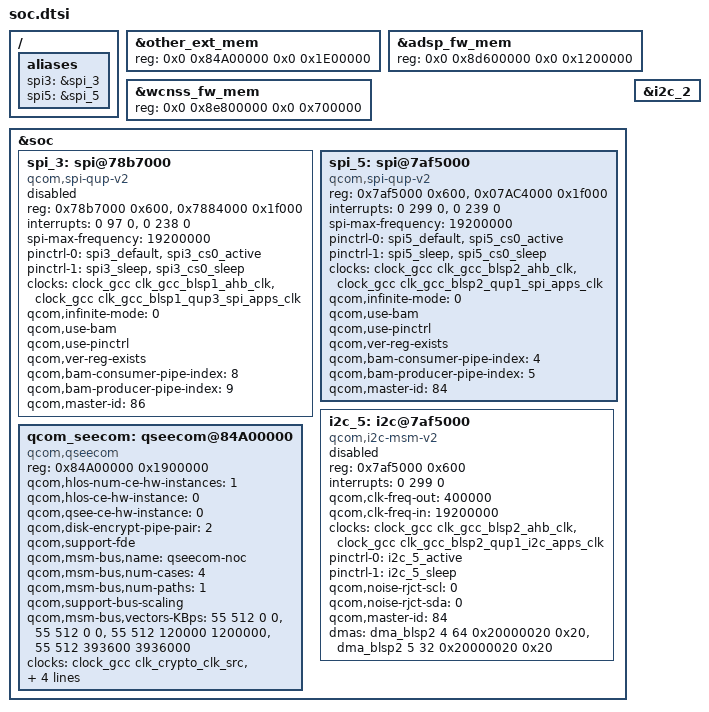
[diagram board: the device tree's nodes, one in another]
/* msm8953-ysl.dtsi */

/* msm8953.dtsi */
&other_ext_mem {
	reg = <0x0 0x84A00000 0x0 0x1E00000>;
};
&adsp_fw_mem {
	reg = <0x0 0x8d600000 0x0 0x1200000>;
};
&wcnss_fw_mem {
	reg = <0x0 0x8e800000 0x0 0x700000>;
};

/ {
	aliases {
		spi3 = &spi_3;
		spi5 = &spi_5;
	};
};

&soc {
      spi_3: spi@78b7000 { /* BLSP1 QUP3 */
		compatible = "qcom,spi-qup-v2";
		#address-cells = <1>;
		#size-cells = <0>;
		reg-names = "spi_physical", "spi_bam_physical";
		reg = <0x78b7000 0x600>,
			<0x7884000 0x1f000>;
		interrupt-names = "spi_irq", "spi_bam_irq";
		interrupts = <0 97 0>, <0 238 0>;
		spi-max-frequency = <19200000>;
		pinctrl-names = "spi_default", "spi_sleep";
		pinctrl-0 = <&spi3_default &spi3_cs0_active>;
		pinctrl-1 = <&spi3_sleep &spi3_cs0_sleep>;
		clocks = <&clock_gcc clk_gcc_blsp1_ahb_clk>,
			<&clock_gcc clk_gcc_blsp1_qup3_spi_apps_clk>;
		clock-names = "iface_clk", "core_clk";
		qcom,infinite-mode = <0>;
		qcom,use-bam;
		qcom,use-pinctrl;
		qcom,ver-reg-exists;
		qcom,bam-consumer-pipe-index = <8>;
		qcom,bam-producer-pipe-index = <9>;
		qcom,master-id = <86>;
		status = "disabled";
	};
	spi_5: spi@7af5000 { /* BLSP2 QUP1 */
		compatible = "qcom,spi-qup-v2";
		#address-cells = <1>;
		#size-cells = <0>;
		reg-names = "spi_physical", "spi_bam_physical";
		reg = <0x7af5000 0x600>,
			<0x07AC4000 0x1f000>;
		interrupt-names = "spi_irq", "spi_bam_irq";
		interrupts = <0 299 0>, <0 239 0>;
		spi-max-frequency = <19200000>;
		pinctrl-names = "spi_default", "spi_sleep";
		pinctrl-0 = <&spi5_default &spi5_cs0_active>;
		pinctrl-1 = <&spi5_sleep &spi5_cs0_sleep>;
		clocks = <&clock_gcc clk_gcc_blsp2_ahb_clk>,
			<&clock_gcc clk_gcc_blsp2_qup1_spi_apps_clk>;
		clock-names = "iface_clk", "core_clk";
		qcom,infinite-mode = <0>;
		qcom,use-bam;
		qcom,use-pinctrl;
		qcom,ver-reg-exists;
		qcom,bam-consumer-pipe-index = <4>;
		qcom,bam-producer-pipe-index = <5>;
		qcom,master-id = <84>;
	};

	i2c_5: i2c@7af5000 { /* BLSP2 QUP1 */
		status = "disabled"; //diabale i2c-5 by henry.liu 2018.12.29
		compatible = "qcom,i2c-msm-v2";
		#address-cells = <1>;
		#size-cells = <0>;
		reg-names = "qup_phys_addr";
		reg = <0x7af5000 0x600>;
		interrupt-names = "qup_irq";
		interrupts = <0 299 0>;
		qcom,clk-freq-out = <400000>;
		qcom,clk-freq-in  = <19200000>;
		clock-names = "iface_clk", "core_clk";
		clocks = <&clock_gcc clk_gcc_blsp2_ahb_clk>,
			<&clock_gcc clk_gcc_blsp2_qup1_i2c_apps_clk>;

		pinctrl-names = "i2c_active", "i2c_sleep";
		pinctrl-0 = <&i2c_5_active>;
		pinctrl-1 = <&i2c_5_sleep>;
		qcom,noise-rjct-scl = <0>;
		qcom,noise-rjct-sda = <0>;
		qcom,master-id = <84>;
		dmas = <&dma_blsp2 4 64 0x20000020 0x20>,
			<&dma_blsp2 5 32 0x20000020 0x20>;
		dma-names = "tx", "rx";
	};
};
&i2c_2 {
	/delete-node/ adv7533@39;
};
&soc {
	/delete-node/ qseecom@85b00000;
	qcom_seecom: qseecom@84A00000 {
		compatible = "qcom,qseecom";
		reg = <0x84A00000 0x1900000>;
		reg-names = "secapp-region";
		qcom,hlos-num-ce-hw-instances = <1>;
		qcom,hlos-ce-hw-instance = <0>;
		qcom,qsee-ce-hw-instance = <0>;
		qcom,disk-encrypt-pipe-pair = <2>;
		qcom,support-fde;
		qcom,msm-bus,name = "qseecom-noc";
		qcom,msm-bus,num-cases = <4>;
		qcom,msm-bus,num-paths = <1>;
		qcom,support-bus-scaling;
		qcom,msm-bus,vectors-KBps =
			<55 512 0 0>,
			<55 512 0 0>,
			<55 512 120000 1200000>,
			<55 512 393600 3936000>;
		clocks = <&clock_gcc clk_crypto_clk_src>,
			 <&clock_gcc clk_gcc_crypto_clk>,
			 <&clock_gcc clk_gcc_crypto_ahb_clk>,
			 <&clock_gcc clk_gcc_crypto_axi_clk>;
		clock-names = "core_clk_src", "core_clk",
				"iface_clk", "bus_clk";
		qcom,ce-opp-freq = <100000000>;
	};
};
